# MB9BF51xR register map
File version: 1.7
CPU: 
Registers are 8-bit, read-write, reset 0x0 unless marked. A register's access mark holds for its fields unless they carry their own. Offsets are from the block's base; [hi:lo] are bit positions; {n}, {i} and the like mark numbered series.

## WC — Watch Counter
Base 0x4003A000
0x00 WCRD ro — Watch Counter Read Register
  [5:0] CTR — counter value
0x01 WCRL — Watch Counter Reload Register
  [5:0] RLC — reload value
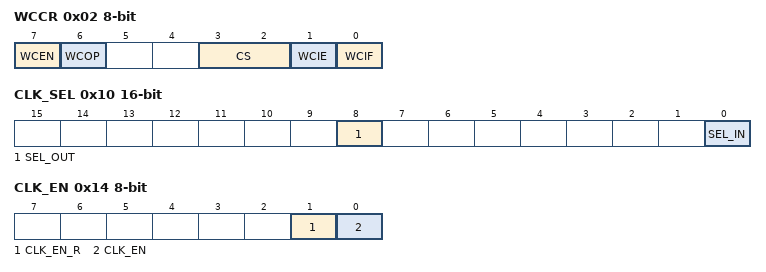
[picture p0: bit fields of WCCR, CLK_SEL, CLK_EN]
0x02 WCCR — Watch Counter Control Register
  [7] WCEN — Watch counter operation enable bit
  [6] WCOP ro — Watch counter operating state flag
  [3:2] CS — Count clock select bits
  [1] WCIE — Interrupt request enable bit
  [0] WCIF — Interrupt request flag bit
0x10 CLK_SEL 16-bit — Clock Selection Register
  [8] SEL_OUT — Output clock selection bit
  [0] SEL_IN — Input clock selection bit
0x14 CLK_EN — Division Clock Enable Register
  [1] CLK_EN_R — Division clock enable read bit
  [0] CLK_EN — Division clock enable bit

## EXTI — External Interrupt and NMI Control
Base 0x40030000
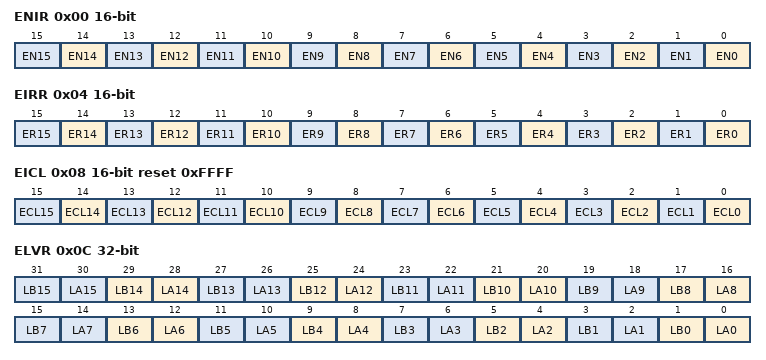
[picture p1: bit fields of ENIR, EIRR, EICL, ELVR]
0x00 ENIR 16-bit — Enable Interrupt Request Register
  [n] EN{n} (n=0..15) — Bit{n} of ENIR
0x04 EIRR 16-bit ro reset not defined — External Interrupt Request Register
  [n] ER{n} (n=0..15) — Bit{n} of EIRR
0x08 EICL 16-bit reset 0xFFFF — External Interrupt Clear Register
  [n] ECL{n} (n=0..15) — Bit{n} of EICL
0x0C ELVR 32-bit — External Interrupt Level Register
  [2n+1] LB{n} (n=0..15) — Bit{2n+1} of ELVR
  [2n] LA{n} (n=0..15) — Bit{2n} of ELVR
0x14 NMIRR ro — Non Maskable Interrupt Request Register
  [0] NR — NMI interrupt request detection bit
0x18 NMICL reset 0x1 — Non Maskable Interrupt Clear Register
  [0] NCL — NMI interrupt cause clear bit

## LVD — Low-voltage Detection
Base 0x40035000
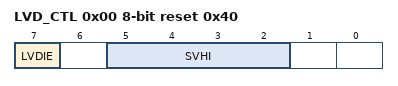
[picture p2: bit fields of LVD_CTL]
0x00 LVD_CTL reset 0x40 — Low-voltage Detection Voltage Control Register
  [7] LVDIE — Low-voltage detection interrupt enable bit
  [5:2] SVHI — Low-voltage detection interrupt voltage setting bits
0x04 LVD_STR ro — Low-voltage Detection Interrupt Register
  [7] LVDIR — Low-voltage detection interrupt bit
0x08 LVD_CLR reset 0x80 — Low-voltage Detection Interrupt Clear Register
  [7] LVDCL — Low-voltage detection interrupt clear bit
0x0C LVD_RLR 32-bit reset 0x1 — Low-voltage Detection Voltage Protection Register
  [31:0] LVDLCK — Low-voltage Detection Voltage Control Register protection bits
0x10 LVD_STR2 ro reset 0x40 — Low-voltage Detection Circuit Status Register
  [7] LVDIRDY — Low-voltage detection interrupt status flag

## MFS_NFC — I2C Auxiliary Noise Filter Setting Register
Base 0x40038800
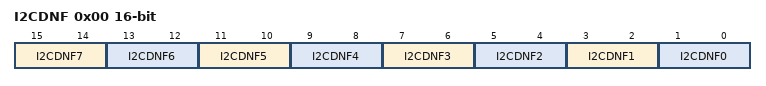
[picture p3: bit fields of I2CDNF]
0x00 I2CDNF 16-bit — I2C Auxiliary Noise Filter Setting Register
  [15:14] I2CDNF7 — Auxiliary noise filter additional step select bits for I2C ch.7
  [13:12] I2CDNF6 — Auxiliary noise filter additional step select bits for I2C ch.6
  [11:10] I2CDNF5 — Auxiliary noise filter additional step select bits for I2C ch.5
  [9:8] I2CDNF4 — Auxiliary noise filter additional step select bits for I2C ch.4
  [7:6] I2CDNF3 — Auxiliary noise filter additional step select bits for I2C ch.3
  [5:4] I2CDNF2 — Auxiliary noise filter additional step select bits for I2C ch.2
  [3:2] I2CDNF1 — Auxiliary noise filter additional step select bits for I2C ch.1
  [1:0] I2CDNF0 — Auxiliary noise filter additional step select bits for I2C ch.0

## CRC — CRC Registers
Base 0x40039000
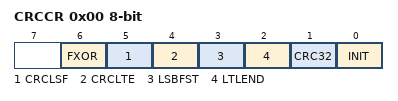
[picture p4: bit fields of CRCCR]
0x00 CRCCR — CRC Control Register
  [6] FXOR — Initialization bit
  [5] CRCLSF — Final XOR control bit
  [4] CRCLTE — CRC result bit-order setting bit
  [3] LSBFST — CRC result byte-order setting bit
  [2] LTLEND — Bit-order setting bit
  [1] CRC32 — Byte-order setting bit
  [0] INIT — CRC mode selection bit
0x04 CRCINIT 32-bit reset 0xFFFFFFFF — Initial Value Register
  [31:0] D — Initial value
0x08 CRCIN 32-bit — Input Data Register
  [31:0] D — Input data
0x0C CRCR 32-bit ro reset 0xFFFFFFFF — CRC Register
  [31:0] D — CRC Data

## EXBUS — External Bus Interface
Base 0x4003F000
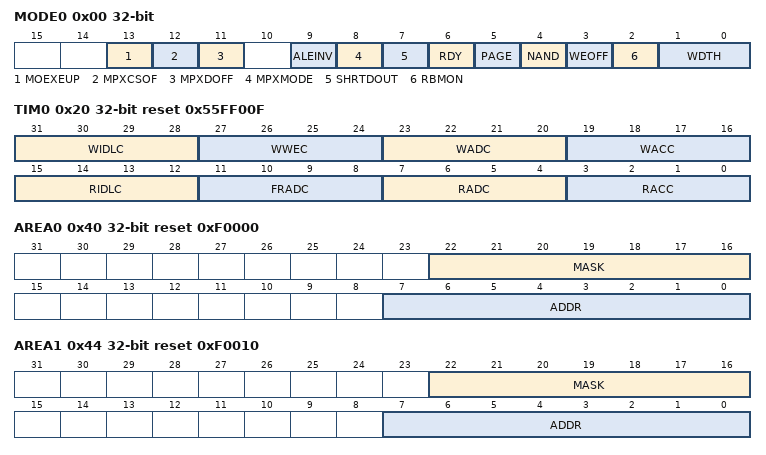
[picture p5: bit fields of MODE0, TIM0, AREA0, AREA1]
0x00 MODE0 32-bit — Mode Register 0
  [13] MOEXEUP — select how to set the MOEX width
  [12] MPXCSOF — select a CS assertion from the start of accessing to the end of address output
  [11] MPXDOFF — select whether or not the address is output to the data lines in multiplex mode
  [9] ALEINV — set up the polarity of the ALE signal
  [8] MPXMODE — select operation bus mode
  [7] SHRTDOUT — select to which idle cycle the write data output is extended
  [6] RDY — control the external RDY function
  [5] PAGE — NOR Flash memory page access mode
  [4] NAND — NAND Flash memory mode
  [3] WEOFF — disable the write enable signal (MWEX) operation
  [2] RBMON — Read Byte Mask ON
  [1:0] WDTH — specify Data Width
{0x0+4i} MODE{i} 32-bit reset not defined (i=1..7) — Mode Register {i}
0x20 TIM0 32-bit reset 0x55FF00F — Timing Register 0
  [31:28] WIDLC — Write Idle Cycle
  [27:24] WWEC — Write Enable Cycle
  [23:20] WADC — Write Address Setup cycle
  [19:16] WACC — Write Access Cycle
  [15:12] RIDLC — Read Idle Cycle
  [11:8] FRADC — First Read Address Cycle
  [7:4] RADC — Read Address Setup cycle
  [3:0] RACC — Read Access Cycle
{0x20+4i} TIM{i} 32-bit reset not defined (i=1..7) — Timing Register {i}
0x40 AREA0 32-bit reset 0xF0000 — Area Register 0
  [22:16] MASK — address mask
  [7:0] ADDR — Address
0x44 AREA1 32-bit reset 0xF0010 — Area Register 1
  [22:16] MASK — address mask
  [7:0] ADDR — Address
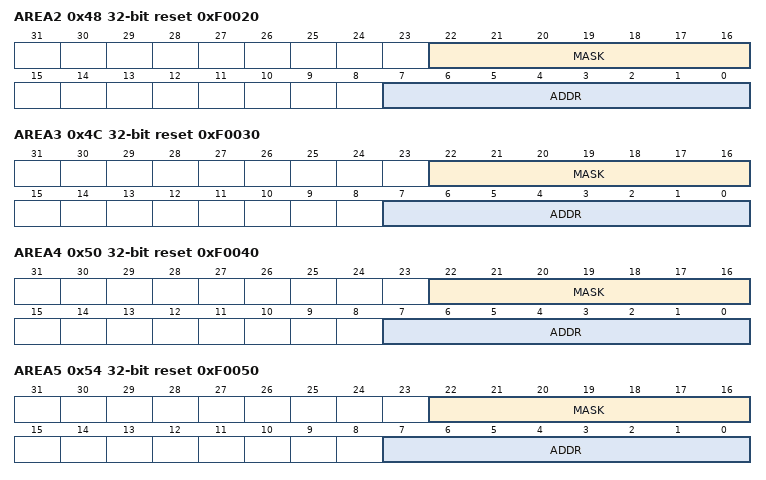
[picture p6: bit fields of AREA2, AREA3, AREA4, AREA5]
0x48 AREA2 32-bit reset 0xF0020 — Area Register 2
  [22:16] MASK — address mask
  [7:0] ADDR — Address
0x4C AREA3 32-bit reset 0xF0030 — Area Register 3
  [22:16] MASK — address mask
  [7:0] ADDR — Address
0x50 AREA4 32-bit reset 0xF0040 — Area Register 4
  [22:16] MASK — address mask
  [7:0] ADDR — Address
0x54 AREA5 32-bit reset 0xF0050 — Area Register 5
  [22:16] MASK — address mask
  [7:0] ADDR — Address
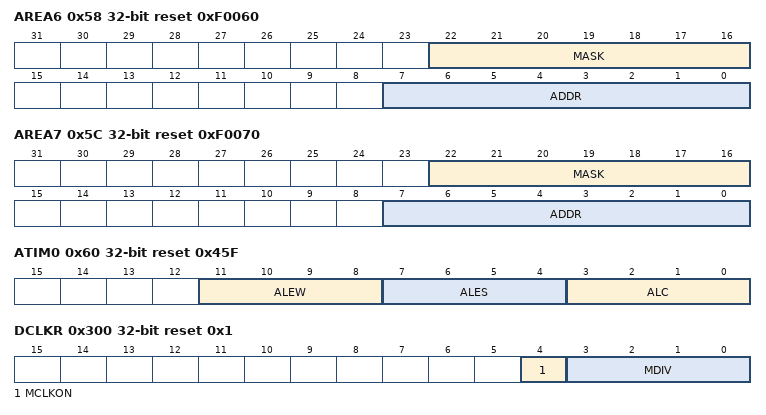
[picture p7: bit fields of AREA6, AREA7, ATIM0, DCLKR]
0x58 AREA6 32-bit reset 0xF0060 — Area Register 6
  [22:16] MASK — address mask
  [7:0] ADDR — Address
0x5C AREA7 32-bit reset 0xF0070 — Area Register 7
  [22:16] MASK — address mask
  [7:0] ADDR — Address
0x60 ATIM0 32-bit reset 0x45F — ALE Timing Register 0
  [11:8] ALEW — Address Latch Enable Width
  [7:4] ALES — Address Latch Enable Setup cycle
  [3:0] ALC — Address Latch Cycle
{0x60+4i} ATIM{i} 32-bit reset not defined (i=1..7) — ALE Timing Register {i}
0x300 DCLKR 32-bit reset 0x1 (reset mask 0xF) — Division Clock Register
  [4] MCLKON
  [3:0] MDIV — MCLK Division Ratio Setup

## USBCLK — USB Clock
Base 0x40036000
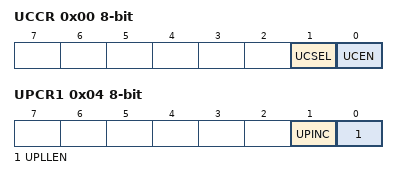
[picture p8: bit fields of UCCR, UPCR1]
0x00 UCCR — USB Clock Control Register
  [1] UCSEL — USB clock selection bit
  [0] UCEN — USB clock output enable bit
0x04 UPCR1 — USB-PLL Control Register 1
  [1] UPINC — USB-PLL input clock selection bit
  [0] UPLLEN — USB-PLL oscillation enable bit
0x08 UPCR2 — USB-PLL Control Register 2
  [2:0] UPOWT — USB-PLL oscillation stabilization wait time setting bit
0x0C UPCR3 — USB-PLL Control Register 3
  [4:0] UPLLK — Frequency division ratio (K) setting bit of the USB-PLL clock
0x10 UPCR4 reset 0x3B — USB-PLL Control Register 4
  [6:0] UPLLN — Frequency division ratio (N) setting bit of the USB-PLL clock
0x14 UP_STR ro — USB-PLL Status Register
  [0] UPRDY — USB-PLL oscillation stabilization bit
0x18 UPINT_ENR — USB-PLL Interrupt Source Enable Register
  [0] UPCSE — USB-PLL oscillation stabilization wait complete interrupt enable bit
0x1C UPINT_CLR wo — USB-PLL Interrupt Source Clear Register
  [0] UPCSC — USB-PLL oscillation stabilization interrupt source clear bit
0x20 UPINT_STR ro — USB-PLL Interrupt Source Status Register
  [0] UPCSI — USB-PLL interrupt source status bit
0x24 UPCR5 reset 0x4 — USB-PLL Control Register 5
  [3:0] UPLLM — Frequency division ratio (M) setting bit of the USB-PLL clock
0x30 USBEN — USB Enable Register
  [0] USBEN — USB enable bit

## DMAC — DMAC Registers
Base 0x40060000
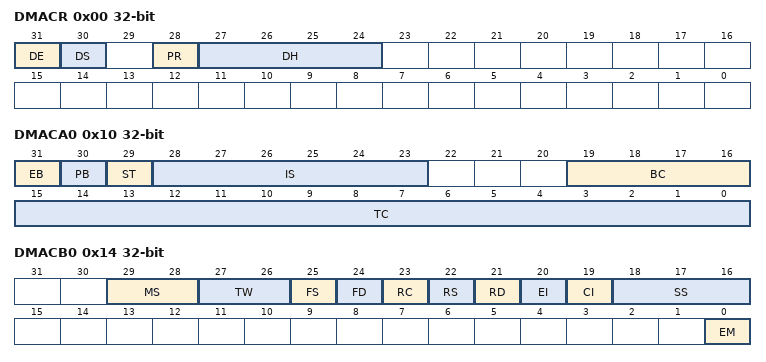
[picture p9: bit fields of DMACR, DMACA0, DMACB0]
0x00 DMACR 32-bit — Entire DMAC Configuration Register
  [31] DE — DMA Enable (all-channel operation enable bit)
  [30] DS — DMA Stop
  [28] PR — Priority Rotation
  [27:24] DH — DMA Halt (All-channel pause bit)
0x10 DMACA0 32-bit — Configuration A Register
  [31] EB — Enable bit (individual-channel operation enable bit)
  [30] PB — Pause bit (individual-channel pause bit)
  [29] ST — Software Trigger
  [28:23] IS — Input Select
  [19:16] BC — Block Count
  [15:0] TC — Transfer Count
0x14 DMACB0 32-bit — Configuration B Register
  [29:28] MS — Mode Select
  [27:26] TW — Transfer Width
  [25] FS — Fixed Source
  [24] FD — Fixed Destination
  [23] RC — Reload Count (BC/TC reload)
  [22] RS — Reload Source
  [21] RD — Reload Destination
  [20] EI — Error Interrupt (unsuccessful transfer completion interrupt enable)
  [19] CI — Completion Interrupt (successful transfer completion interrupt enable)
  [18:16] SS — Stop Status (stop status notification)
  [0] EM — Enable bit Mask (EB bit clear mask)
0x18 DMACSA0 32-bit — Transfer Source Address Register
0x1C DMACDA0 32-bit — Transfer Destination Address Register
{0x10+0x10*i} DMACA{i} 32-bit reset not defined (i=1..7) — Configuration A Register {i}
{0x14+0x10*i} DMACB{i} 32-bit reset not defined (i=1..7) — Configuration B Register {i}
{0x18+0x10*i} DMACSA{i} 32-bit reset not defined (i=1..7) — Transfer Source Address Register {i}
{0x1C+0x10*i} DMACDA{i} 32-bit reset not defined (i=1..7) — Transfer Destination Address Register {i}

## CANPRES — CAN Prescaler Register
Base 0x40037000
0x00 CANPRE reset 0xB (reset mask 0xF) — CAN Prescaler Register
